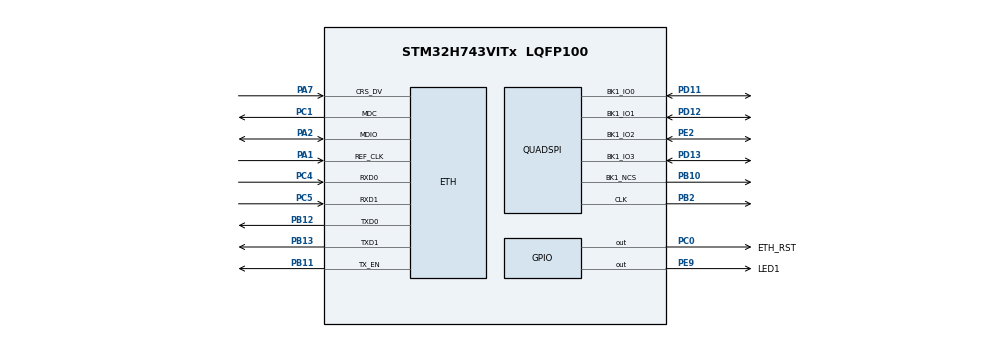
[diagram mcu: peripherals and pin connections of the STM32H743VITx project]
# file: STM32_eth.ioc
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CORTEX_M7.AccessPermission_S-Cortex_Memory_Protection_Unit_Region1_Settings_S=MPU_REGION_FULL_ACCESS
CORTEX_M7.AccessPermission_S-Cortex_Memory_Protection_Unit_Region2_Settings_S=MPU_REGION_FULL_ACCESS
CORTEX_M7.AccessPermission_S-Cortex_Memory_Protection_Unit_Region3_Settings_S=MPU_REGION_FULL_ACCESS
CORTEX_M7.BaseAddress_S-Cortex_Memory_Protection_Unit_Region1_Settings_S=0x30020000
CORTEX_M7.BaseAddress_S-Cortex_Memory_Protection_Unit_Region2_Settings_S=0x30040000
CORTEX_M7.BaseAddress_S-Cortex_Memory_Protection_Unit_Region3_Settings_S=0x24000000
CORTEX_M7.CPU_DCache=Enabled
CORTEX_M7.CPU_ICache=Enabled
CORTEX_M7.DisableExec_S-Cortex_Memory_Protection_Unit_Region1_Settings_S=MPU_INSTRUCTION_ACCESS_DISABLE
CORTEX_M7.DisableExec_S-Cortex_Memory_Protection_Unit_Region2_Settings_S=MPU_INSTRUCTION_ACCESS_DISABLE
CORTEX_M7.Enable_S-Cortex_Memory_Protection_Unit_Region1_Settings_S=MPU_REGION_ENABLE
CORTEX_M7.Enable_S-Cortex_Memory_Protection_Unit_Region2_Settings_S=MPU_REGION_ENABLE
CORTEX_M7.Enable_S-Cortex_Memory_Protection_Unit_Region3_Settings_S=MPU_REGION_ENABLE
CORTEX_M7.IsBufferable_S-Cortex_Memory_Protection_Unit_Region2_Settings_S=MPU_ACCESS_BUFFERABLE
CORTEX_M7.IsCacheable_S-Cortex_Memory_Protection_Unit_Region3_Settings_S=MPU_ACCESS_CACHEABLE
CORTEX_M7.IsShareable_S-Cortex_Memory_Protection_Unit_Region2_Settings_S=MPU_ACCESS_SHAREABLE
CORTEX_M7.IsShareable_S-Cortex_Memory_Protection_Unit_Region3_Settings_S=MPU_ACCESS_SHAREABLE
CORTEX_M7.Size_S-Cortex_Memory_Protection_Unit_Region1_Settings_S=MPU_REGION_SIZE_128KB
CORTEX_M7.Size_S-Cortex_Memory_Protection_Unit_Region2_Settings_S=MPU_REGION_SIZE_512B
CORTEX_M7.Size_S-Cortex_Memory_Protection_Unit_Region3_Settings_S=MPU_REGION_SIZE_512KB
CORTEX_M7.TypeExtField_S-Cortex_Memory_Protection_Unit_Region1_Settings_S=MPU_TEX_LEVEL1
CORTEX_M7.default_mode_Activation=1
ETH.MediaInterface=HAL_ETH_RMII_MODE
FREERTOS.Tasks01=defaultTask,24,2048,StartDefaultTask,Default,NULL,Dynamic,NULL,NULL
LWIP.BSP.number=1
LWIP.GATEWAY_ADDRESS=192.168.001.001
LWIP.IP_ADDRESS=192.168.001.010
LWIP.LWIP_DHCP=0
LWIP.LWIP_RAM_HEAP_POINTER=0x30020000
LWIP.MEM_SIZE=131048
LWIP.NETMASK_ADDRESS=255.255.255.000
LWIP.Version=v2.1.2_Cube
LWIP0.BSP.STBoard=false
LWIP0.BSP.api=BSP_COMPONENT_DRIVER
LWIP0.BSP.component=LAN8742
LWIP0.BSP.instance=LAN8742
LWIP0.BSP.name=Driver_PHY
LWIP0.BSP.semaphore=S_LAN8742
LWIP0.BSP.solution=LAN8742
Mcu.Family=STM32H7
Mcu.Name=STM32H743VITx
Mcu.Package=LQFP100
NVIC.ETH_IRQn=true\:5\:0\:true\:false\:true\:true\:true\:true\:true
NVIC.PriorityGroup=NVIC_PRIORITYGROUP_4
NVIC.TIM6_DAC_IRQn=true\:15\:0\:false\:false\:true\:false\:false\:true\:true
NVIC.TimeBase=TIM6_DAC_IRQn
NVIC.TimeBaseIP=TIM6
PA1.GPIO_Speed_Default_HIGH=GPIO_SPEED_FREQ_VERY_HIGH
PA1.Mode=RMII
PA1.Signal=ETH_REF_CLK
PA2.GPIO_Speed_Default_HIGH=GPIO_SPEED_FREQ_VERY_HIGH
PA2.Mode=RMII
PA2.Signal=ETH_MDIO
PA7.GPIO_Speed_Default_HIGH=GPIO_SPEED_FREQ_VERY_HIGH
PA7.Mode=RMII
PA7.Signal=ETH_CRS_DV
PB10.GPIO_Speed=GPIO_SPEED_FREQ_VERY_HIGH
PB10.Mode=Single Bank 1
PB10.Signal=QUADSPI_BK1_NCS
PB11.GPIO_Speed_Default_HIGH=GPIO_SPEED_FREQ_VERY_HIGH
PB11.Mode=RMII
PB11.Signal=ETH_TX_EN
PB12.GPIO_Speed_Default_HIGH=GPIO_SPEED_FREQ_VERY_HIGH
PB12.Mode=RMII
PB12.Signal=ETH_TXD0
PB13.GPIO_Speed_Default_HIGH=GPIO_SPEED_FREQ_VERY_HIGH
PB13.Mode=RMII
PB13.Signal=ETH_TXD1
PB2.GPIO_Speed=GPIO_SPEED_FREQ_VERY_HIGH
PB2.Mode=Single Bank 1
PB2.Signal=QUADSPI_CLK
PC0.GPIO_Label=ETH_RST
PC0.GPIO_Speed=GPIO_SPEED_FREQ_HIGH
PC0.Signal=GPIO_Output
PC1.GPIO_Speed_Default_HIGH=GPIO_SPEED_FREQ_VERY_HIGH
PC1.Mode=RMII
PC1.Signal=ETH_MDC
PC4.GPIO_Speed_Default_HIGH=GPIO_SPEED_FREQ_VERY_HIGH
PC4.Mode=RMII
PC4.Signal=ETH_RXD0
PC5.GPIO_Speed_Default_HIGH=GPIO_SPEED_FREQ_VERY_HIGH
PC5.Mode=RMII
PC5.Signal=ETH_RXD1
PD11.GPIO_Speed=GPIO_SPEED_FREQ_VERY_HIGH
PD11.Mode=Single Bank 1
PD11.Signal=QUADSPI_BK1_IO0
PD12.GPIO_Speed=GPIO_SPEED_FREQ_VERY_HIGH
PD12.Mode=Single Bank 1
PD12.Signal=QUADSPI_BK1_IO1
PD13.GPIO_Speed=GPIO_SPEED_FREQ_VERY_HIGH
PD13.Mode=Single Bank 1
PD13.Signal=QUADSPI_BK1_IO3
PE2.GPIO_Speed=GPIO_SPEED_FREQ_VERY_HIGH
PE2.Mode=Single Bank 1
PE2.Signal=QUADSPI_BK1_IO2
PE9.GPIO_Label=LED1
PE9.PinState=GPIO_PIN_RESET
PE9.Signal=GPIO_Output
PH0-OSC_IN\ (PH0).Mode=HSE-External-Clock-Source
PH0-OSC_IN\ (PH0).Signal=RCC_OSC_IN
ProjectManager.HeapSize=0x200
ProjectManager.StackSize=0x400
ProjectManager.TargetToolchain=STM32CubeIDE
QUADSPI.ChipSelectHighTime=QSPI_CS_HIGH_TIME_2_CYCLE
QUADSPI.ClockPrescaler=2
QUADSPI.FifoThreshold=32
QUADSPI.FlashSize=24
QUADSPI.SampleShifting=QSPI_SAMPLE_SHIFTING_HALFCYCLE
RCC.ADCFreq_Value=129000000
RCC.APB1Freq_Value=100000000
RCC.APB2Freq_Value=100000000
RCC.APB3Freq_Value=100000000
RCC.APB4Freq_Value=100000000
RCC.CortexFreq_Value=400000000
RCC.D1PPRE=RCC_APB3_DIV2
RCC.D2PPRE1=RCC_APB1_DIV2
RCC.D2PPRE2=RCC_APB2_DIV2
RCC.D3PPRE=RCC_APB4_DIV2
RCC.DIVN1=400
RCC.HCLKFreq_Value=200000000
RCC.HPRE=RCC_HCLK_DIV2
RCC.SYSCLKFreq_VALUE=400000000
RCC.SYSCLKSource=RCC_SYSCLKSOURCE_PLLCLK
RCC.USBFreq_Value=400000000
VP_FREERTOS_VS_CMSIS_V2.Mode=CMSIS_V2
VP_LWIP_VS_Enabled.Mode=Enabled
VP_MEMORYMAP_VS_MEMORYMAP.Mode=CurAppReg
VP_RTC_VS_RTC_Activate.Mode=RTC_Enabled
VP_RTC_VS_RTC_Calendar.Mode=RTC_Calendar
VP_SYS_VS_tim6.Mode=TIM6
board=custom

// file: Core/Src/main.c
/* USER CODE BEGIN Header */
/**
  ******************************************************************************
  * @file           : main.c
  * @brief          : Main program body
  ******************************************************************************
  * @attention
  *
  * Copyright (c) 2026 STMicroelectronics.
  * All rights reserved.
  *
  * This software is licensed under terms that can be found in the LICENSE file
  * in the root directory of this software component.
  * If no LICENSE file comes with this software, it is provided AS-IS.
  *
  ******************************************************************************
  */
/* USER CODE END Header */
#include "main.h"
#include "cmsis_os.h"
#include "lwip.h"

/* USER CODE BEGIN Includes */
#include "udp.h"
#include <string.h>
#include "lwiperf.h"
/* USER CODE END Includes */

QSPI_HandleTypeDef hqspi;

RTC_HandleTypeDef hrtc;

/* Definitions for defaultTask */
osThreadId_t defaultTaskHandle;
const osThreadAttr_t defaultTask_attributes = {
  .name = "defaultTask",
  .stack_size = 2048 * 4,
  .priority = (osPriority_t) osPriorityNormal,
};

void SystemClock_Config(void);
static void MPU_Config(void);
static void MX_GPIO_Init(void);
static void MX_QUADSPI_Init(void);
static void MX_RTC_Init(void);
void StartDefaultTask(void *argument);

int main(void)
{

  /* MPU Configuration--------------------------------------------------------*/
  MPU_Config();

  /* Enable the CPU Cache */

  /* Enable I-Cache---------------------------------------------------------*/
  SCB_EnableICache();

  /* Enable D-Cache---------------------------------------------------------*/
  SCB_EnableDCache();

  /* MCU Configuration--------------------------------------------------------*/

  /* Reset of all peripherals, Initializes the Flash interface and the Systick. */
  HAL_Init();

  /* Configure the system clock */
  SystemClock_Config();

  /* Initialize all configured peripherals */
  MX_GPIO_Init();
  MX_QUADSPI_Init();
  MX_RTC_Init();

  /* Init scheduler */
  osKernelInitialize();

  /* Create the thread(s) */
  /* creation of defaultTask */
  defaultTaskHandle = osThreadNew(StartDefaultTask, NULL, &defaultTask_attributes);

  /* Start scheduler */
  osKernelStart();

  /* We should never get here as control is now taken by the scheduler */

  /* Infinite loop */
  while (1)
  {

    /* USER CODE BEGIN 3 */
//	  HAL_GPIO_TogglePin(GPIOE,GPIO_PIN_9);
//	 HAL_Delay(1000);
  }
  /* USER CODE END 3 */
}

void SystemClock_Config(void)
{
  RCC_OscInitTypeDef RCC_OscInitStruct = {0};
  RCC_ClkInitTypeDef RCC_ClkInitStruct = {0};

  /** Supply configuration update enable
  */
  HAL_PWREx_ConfigSupply(PWR_LDO_SUPPLY);

  /** Configure the main internal regulator output voltage
  */
  __HAL_PWR_VOLTAGESCALING_CONFIG(PWR_REGULATOR_VOLTAGE_SCALE1);

  while(!__HAL_PWR_GET_FLAG(PWR_FLAG_VOSRDY)) {}

  /** Initializes the RCC Oscillators according to the specified parameters
  * in the RCC_OscInitTypeDef structure.
  */
  RCC_OscInitStruct.OscillatorType = RCC_OSCILLATORTYPE_HSI|RCC_OSCILLATORTYPE_LSI;
  RCC_OscInitStruct.HSIState = RCC_HSI_DIV1;
  RCC_OscInitStruct.HSICalibrationValue = RCC_HSICALIBRATION_DEFAULT;
  RCC_OscInitStruct.LSIState = RCC_LSI_ON;
  RCC_OscInitStruct.PLL.PLLState = RCC_PLL_ON;
  RCC_OscInitStruct.PLL.PLLSource = RCC_PLLSOURCE_HSI;
  RCC_OscInitStruct.PLL.PLLM = 32;
  RCC_OscInitStruct.PLL.PLLN = 400;
  RCC_OscInitStruct.PLL.PLLP = 2;
  RCC_OscInitStruct.PLL.PLLQ = 2;
  RCC_OscInitStruct.PLL.PLLR = 2;
  RCC_OscInitStruct.PLL.PLLRGE = RCC_PLL1VCIRANGE_1;
  RCC_OscInitStruct.PLL.PLLVCOSEL = RCC_PLL1VCOWIDE;
  RCC_OscInitStruct.PLL.PLLFRACN = 0;
  if (HAL_RCC_OscConfig(&RCC_OscInitStruct) != HAL_OK)
  {
    Error_Handler();
  }

  /** Initializes the CPU, AHB and APB buses clocks
  */
  RCC_ClkInitStruct.ClockType = RCC_CLOCKTYPE_HCLK|RCC_CLOCKTYPE_SYSCLK
                              |RCC_CLOCKTYPE_PCLK1|RCC_CLOCKTYPE_PCLK2
                              |RCC_CLOCKTYPE_D3PCLK1|RCC_CLOCKTYPE_D1PCLK1;
  RCC_ClkInitStruct.SYSCLKSource = RCC_SYSCLKSOURCE_PLLCLK;
  RCC_ClkInitStruct.SYSCLKDivider = RCC_SYSCLK_DIV1;
  RCC_ClkInitStruct.AHBCLKDivider = RCC_HCLK_DIV2;
  RCC_ClkInitStruct.APB3CLKDivider = RCC_APB3_DIV2;
  RCC_ClkInitStruct.APB1CLKDivider = RCC_APB1_DIV2;
  RCC_ClkInitStruct.APB2CLKDivider = RCC_APB2_DIV2;
  RCC_ClkInitStruct.APB4CLKDivider = RCC_APB4_DIV2;

  if (HAL_RCC_ClockConfig(&RCC_ClkInitStruct, FLASH_LATENCY_2) != HAL_OK)
  {
    Error_Handler();
  }
}

static void MX_QUADSPI_Init(void)
{

  /* QUADSPI parameter configuration*/
  hqspi.Instance = QUADSPI;
  hqspi.Init.ClockPrescaler = 2;
  hqspi.Init.FifoThreshold = 32;
  hqspi.Init.SampleShifting = QSPI_SAMPLE_SHIFTING_HALFCYCLE;
  hqspi.Init.FlashSize = 24;
  hqspi.Init.ChipSelectHighTime = QSPI_CS_HIGH_TIME_2_CYCLE;
  hqspi.Init.ClockMode = QSPI_CLOCK_MODE_0;
  hqspi.Init.FlashID = QSPI_FLASH_ID_1;
  hqspi.Init.DualFlash = QSPI_DUALFLASH_DISABLE;
  if (HAL_QSPI_Init(&hqspi) != HAL_OK)
  {
    Error_Handler();
  }

}

static void MX_RTC_Init(void)
{

  RTC_TimeTypeDef sTime = {0};
  RTC_DateTypeDef sDate = {0};

  /** Initialize RTC Only
  */
  hrtc.Instance = RTC;
  hrtc.Init.HourFormat = RTC_HOURFORMAT_24;
  hrtc.Init.AsynchPrediv = 127;
  hrtc.Init.SynchPrediv = 255;
  hrtc.Init.OutPut = RTC_OUTPUT_DISABLE;
  hrtc.Init.OutPutPolarity = RTC_OUTPUT_POLARITY_HIGH;
  hrtc.Init.OutPutType = RTC_OUTPUT_TYPE_OPENDRAIN;
  hrtc.Init.OutPutRemap = RTC_OUTPUT_REMAP_NONE;
  if (HAL_RTC_Init(&hrtc) != HAL_OK)
  {
    Error_Handler();
  }

  /** Initialize RTC and set the Time and Date
  */
  sTime.Hours = 0x0;
  sTime.Minutes = 0x0;
  sTime.Seconds = 0x0;
  sTime.DayLightSaving = RTC_DAYLIGHTSAVING_NONE;
  sTime.StoreOperation = RTC_STOREOPERATION_RESET;
  if (HAL_RTC_SetTime(&hrtc, &sTime, RTC_FORMAT_BCD) != HAL_OK)
  {
    Error_Handler();
  }
  sDate.WeekDay = RTC_WEEKDAY_MONDAY;
  sDate.Month = RTC_MONTH_JANUARY;
  sDate.Date = 0x1;
  sDate.Year = 0x0;

  if (HAL_RTC_SetDate(&hrtc, &sDate, RTC_FORMAT_BCD) != HAL_OK)
  {
    Error_Handler();
  }

}

static void MX_GPIO_Init(void)
{
  GPIO_InitTypeDef GPIO_InitStruct = {0};

  /* GPIO Ports Clock Enable */
  __HAL_RCC_GPIOE_CLK_ENABLE();
  __HAL_RCC_GPIOH_CLK_ENABLE();
  __HAL_RCC_GPIOC_CLK_ENABLE();
  __HAL_RCC_GPIOA_CLK_ENABLE();
  __HAL_RCC_GPIOB_CLK_ENABLE();
  __HAL_RCC_GPIOD_CLK_ENABLE();

  /*Configure GPIO pin Output Level */
  HAL_GPIO_WritePin(ETH_RST_GPIO_Port, ETH_RST_Pin, GPIO_PIN_RESET);

  /*Configure GPIO pin Output Level */
  HAL_GPIO_WritePin(LED1_GPIO_Port, LED1_Pin, GPIO_PIN_RESET);

  /*Configure GPIO pin : ETH_RST_Pin */
  GPIO_InitStruct.Pin = ETH_RST_Pin;
  GPIO_InitStruct.Mode = GPIO_MODE_OUTPUT_PP;
  GPIO_InitStruct.Pull = GPIO_NOPULL;
  GPIO_InitStruct.Speed = GPIO_SPEED_FREQ_HIGH;
  HAL_GPIO_Init(ETH_RST_GPIO_Port, &GPIO_InitStruct);

  /*Configure GPIO pin : LED1_Pin */
  GPIO_InitStruct.Pin = LED1_Pin;
  GPIO_InitStruct.Mode = GPIO_MODE_OUTPUT_PP;
  GPIO_InitStruct.Pull = GPIO_NOPULL;
  GPIO_InitStruct.Speed = GPIO_SPEED_FREQ_LOW;
  HAL_GPIO_Init(LED1_GPIO_Port, &GPIO_InitStruct);

}

void StartDefaultTask(void *argument)
{
  /* init code for LWIP */
  MX_LWIP_Init();
  /* USER CODE BEGIN 5 */
  init_logger(SYSLOG_SERVER_IP, SYSLOG_SERVER_PORT);
//  LOCK_TCPIP_CORE();
//   lwiperf_start_tcp_server_default(NULL, NULL);
//
//   ip4_addr_t remote_addr;
//   IP4_ADDR(&remote_addr, 192, 168, 1, 1);
//   lwiperf_start_tcp_client_default(&remote_addr, NULL, NULL);
//   UNLOCK_TCPIP_CORE();
  /* Infinite loop */
  for(;;)
  {
    LOG_INFO("LOGGER","syslog test: single thread 1000hz 101\r\n");
    osDelay(1000);
  }
  /* USER CODE END 5 */
}

 /* MPU Configuration */

void MPU_Config(void)
{
  MPU_Region_InitTypeDef MPU_InitStruct = {0};

  /* Disables the MPU */
  HAL_MPU_Disable();

  /** Initializes and configures the Region and the memory to be protected
  */
  MPU_InitStruct.Enable = MPU_REGION_ENABLE;
  MPU_InitStruct.Number = MPU_REGION_NUMBER0;
  MPU_InitStruct.BaseAddress = 0x0;
  MPU_InitStruct.Size = MPU_REGION_SIZE_4GB;
  MPU_InitStruct.SubRegionDisable = 0x87;
  MPU_InitStruct.TypeExtField = MPU_TEX_LEVEL0;
  MPU_InitStruct.AccessPermission = MPU_REGION_NO_ACCESS;
  MPU_InitStruct.DisableExec = MPU_INSTRUCTION_ACCESS_DISABLE;
  MPU_InitStruct.IsShareable = MPU_ACCESS_SHAREABLE;
  MPU_InitStruct.IsCacheable = MPU_ACCESS_NOT_CACHEABLE;
  MPU_InitStruct.IsBufferable = MPU_ACCESS_NOT_BUFFERABLE;

  HAL_MPU_ConfigRegion(&MPU_InitStruct);

  /** Initializes and configures the Region and the memory to be protected
  */
  MPU_InitStruct.Number = MPU_REGION_NUMBER1;
  MPU_InitStruct.BaseAddress = 0x30020000;
  MPU_InitStruct.Size = MPU_REGION_SIZE_128KB;
  MPU_InitStruct.SubRegionDisable = 0x0;
  MPU_InitStruct.TypeExtField = MPU_TEX_LEVEL1;
  MPU_InitStruct.AccessPermission = MPU_REGION_FULL_ACCESS;
  MPU_InitStruct.IsShareable = MPU_ACCESS_NOT_SHAREABLE;

  HAL_MPU_ConfigRegion(&MPU_InitStruct);

  /** Initializes and configures the Region and the memory to be protected
  */
  MPU_InitStruct.Number = MPU_REGION_NUMBER2;
  MPU_InitStruct.BaseAddress = 0x30040000;
  MPU_InitStruct.Size = MPU_REGION_SIZE_512B;
  MPU_InitStruct.TypeExtField = MPU_TEX_LEVEL0;
  MPU_InitStruct.IsShareable = MPU_ACCESS_SHAREABLE;
  MPU_InitStruct.IsBufferable = MPU_ACCESS_BUFFERABLE;

  HAL_MPU_ConfigRegion(&MPU_InitStruct);

  /** Initializes and configures the Region and the memory to be protected
  */
  MPU_InitStruct.Number = MPU_REGION_NUMBER3;
  MPU_InitStruct.BaseAddress = 0x24000000;
  MPU_InitStruct.Size = MPU_REGION_SIZE_512KB;
  MPU_InitStruct.DisableExec = MPU_INSTRUCTION_ACCESS_ENABLE;
  MPU_InitStruct.IsCacheable = MPU_ACCESS_CACHEABLE;
  MPU_InitStruct.IsBufferable = MPU_ACCESS_NOT_BUFFERABLE;

  HAL_MPU_ConfigRegion(&MPU_InitStruct);
  /* Enables the MPU */
  HAL_MPU_Enable(MPU_PRIVILEGED_DEFAULT);

}

void HAL_TIM_PeriodElapsedCallback(TIM_HandleTypeDef *htim)
{
  if (htim->Instance == TIM6)
  {
    HAL_IncTick();
  }
}

void Error_Handler(void)
{
  __disable_irq();
  while (1)
  {
  }
}

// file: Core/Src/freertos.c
/* USER CODE BEGIN Header */
/**
  ******************************************************************************
  * File Name          : freertos.c
  * Description        : Code for freertos applications
  ******************************************************************************
  * @attention
  *
  * Copyright (c) 2026 STMicroelectronics.
  * All rights reserved.
  *
  * This software is licensed under terms that can be found in the LICENSE file
  * in the root directory of this software component.
  * If no LICENSE file comes with this software, it is provided AS-IS.
  *
  ******************************************************************************
  */
/* USER CODE END Header */

#include "FreeRTOS.h"
#include "task.h"
#include "main.h"

/* USER CODE BEGIN Application */
void vApplicationStackOverflowHook(xTaskHandle xTask, signed char *pcTaskName)
{
   /* ETH_CODE: add breakpoint when stack oveflow is detected by FreeRTOS.
    * Useful for debugging issues.
    */
   __BKPT(0);
}
/* USER CODE END Application */
